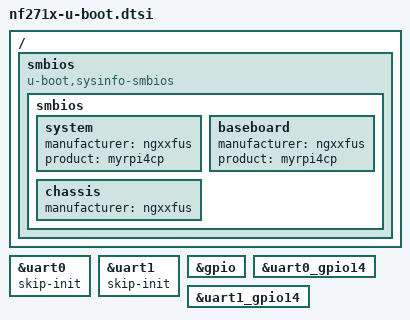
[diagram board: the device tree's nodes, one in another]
// SPDX-License-Identifier: GPL-2.0+
/*
 * U-Boot addition to keep baudrate set by firmware
 * and also initialize before relocation.
 *
 * (C) Copyright 2016 Fabian Vogt <fvogt@suse.com>
 */

/ {
	smbios {
		compatible = "u-boot,sysinfo-smbios";
		smbios {
			system {
				manufacturer = "ngxxfus";
				product = "myrpi4cp";
			};
			baseboard {
				manufacturer = "ngxxfus";
				product = "myrpi4cp";
			};
			chassis {
				manufacturer = "ngxxfus";
			};
		};
	};
};

&uart0 {
	skip-init;
	bootph-all;
};

&uart1 {
	skip-init;
	bootph-all;
};

&gpio {
	bootph-all;
};

&uart0_gpio14 {
	bootph-all;
};

&uart1_gpio14 {
	bootph-all;
};
